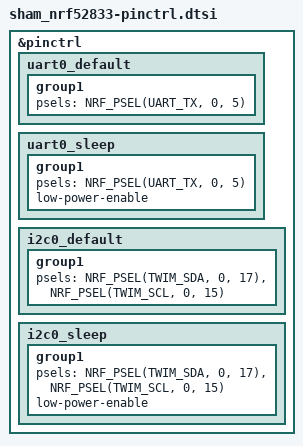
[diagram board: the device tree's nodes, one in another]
/*
 * Copyright (c) 2024 Tareq Mhisen
 */

&pinctrl {
	uart0_default: uart0_default {
		group1 {
			psels = <NRF_PSEL(UART_TX, 0, 5)>;
		};
	};
	uart0_sleep: uart0_sleep {
		group1 {
			psels = <NRF_PSEL(UART_TX, 0, 5)>;
			low-power-enable;
		};
	};

	i2c0_default: i2c0_default {
		group1 {
			psels = <NRF_PSEL(TWIM_SDA, 0, 17)>,
					<NRF_PSEL(TWIM_SCL, 0, 15)>;
		};
	};

	i2c0_sleep: i2c0_sleep {
		group1 {
			psels = <NRF_PSEL(TWIM_SDA, 0, 17)>,
					<NRF_PSEL(TWIM_SCL, 0, 15)>;
			low-power-enable;
		};
	};
};
